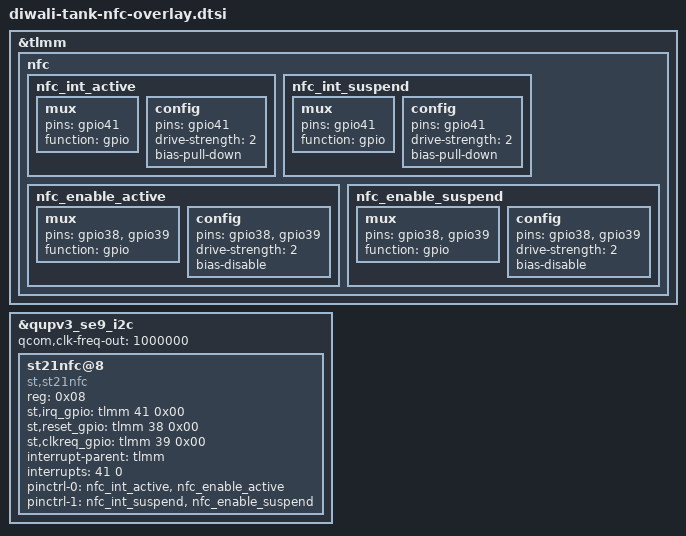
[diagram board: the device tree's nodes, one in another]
/* Copyright (c) 2021, The Linux Foundation. All rights reserved.
 *
 * This program is free software; you can redistribute it and/or modify
 * it under the terms of the GNU General Public License version 2 and
 * only version 2 as published by the Free Software Foundation.
 *
 * This program is distributed in the hope that it will be useful,
 * but WITHOUT ANY WARRANTY; without even the implied warranty of
 * MERCHANTABILITY or FITNESS FOR A PARTICULAR PURPOSE.  See the
 * GNU General Public License for more details.
 */

&tlmm {
	nfc {
		nfc_int_active: nfc_int_active {
			/* active state */
			mux {
				/* NFC Read Interrupt */
				pins = "gpio41";
				function = "gpio";
			};

			config {
				pins = "gpio41";
				drive-strength = <2>; /* 2 MA */
				bias-pull-down;
			};
		};

		nfc_int_suspend: nfc_int_suspend {
			/* sleep state */
			mux {
				/* NFC Read Interrupt */
				pins = "gpio41";
				function = "gpio";
			};

			config {
				pins = "gpio41";
				drive-strength = <2>; /* 2 MA */
				bias-pull-down;
			};
		};

		nfc_enable_active: nfc_enable_active {
			mux {
				/* Enable, Firmware and Clock request gpios */
				pins = "gpio38", "gpio39";
				function = "gpio";
			};

			config {
				pins = "gpio38", "gpio39";
				drive-strength = <2>; /* 2 MA */
				bias-disable;
			};
		};

		nfc_enable_suspend: nfc_enable_suspend {
			mux {
				pins = "gpio38", "gpio39";
				function = "gpio";
			};

			config {
				pins = "gpio38", "gpio39";
				drive-strength = <2>; /* 2 MA */
				bias-disable;
			};
		};
	};
};

&qupv3_se9_i2c {
	status = "ok";
	qcom,clk-freq-out = <1000000>;
	#address-cells = <1>;
	#size-cells = <0>;
	st21nfc@8 {
		compatible = "st,st21nfc";
		reg = <0x08>;
		st,irq_gpio = <&tlmm 41 0x00>;
		st,reset_gpio = <&tlmm 38 0x00>;
		st,clkreq_gpio = <&tlmm 39 0x00>;
		interrupt-parent = <&tlmm>;
		interrupts = <41 0>;
		interrupt-names = "nfc_irq";
		pinctrl-names = "nfc_active", "nfc_suspend";
		pinctrl-0 = <&nfc_int_active &nfc_enable_active>;
		pinctrl-1 = <&nfc_int_suspend &nfc_enable_suspend>;
	};
};

